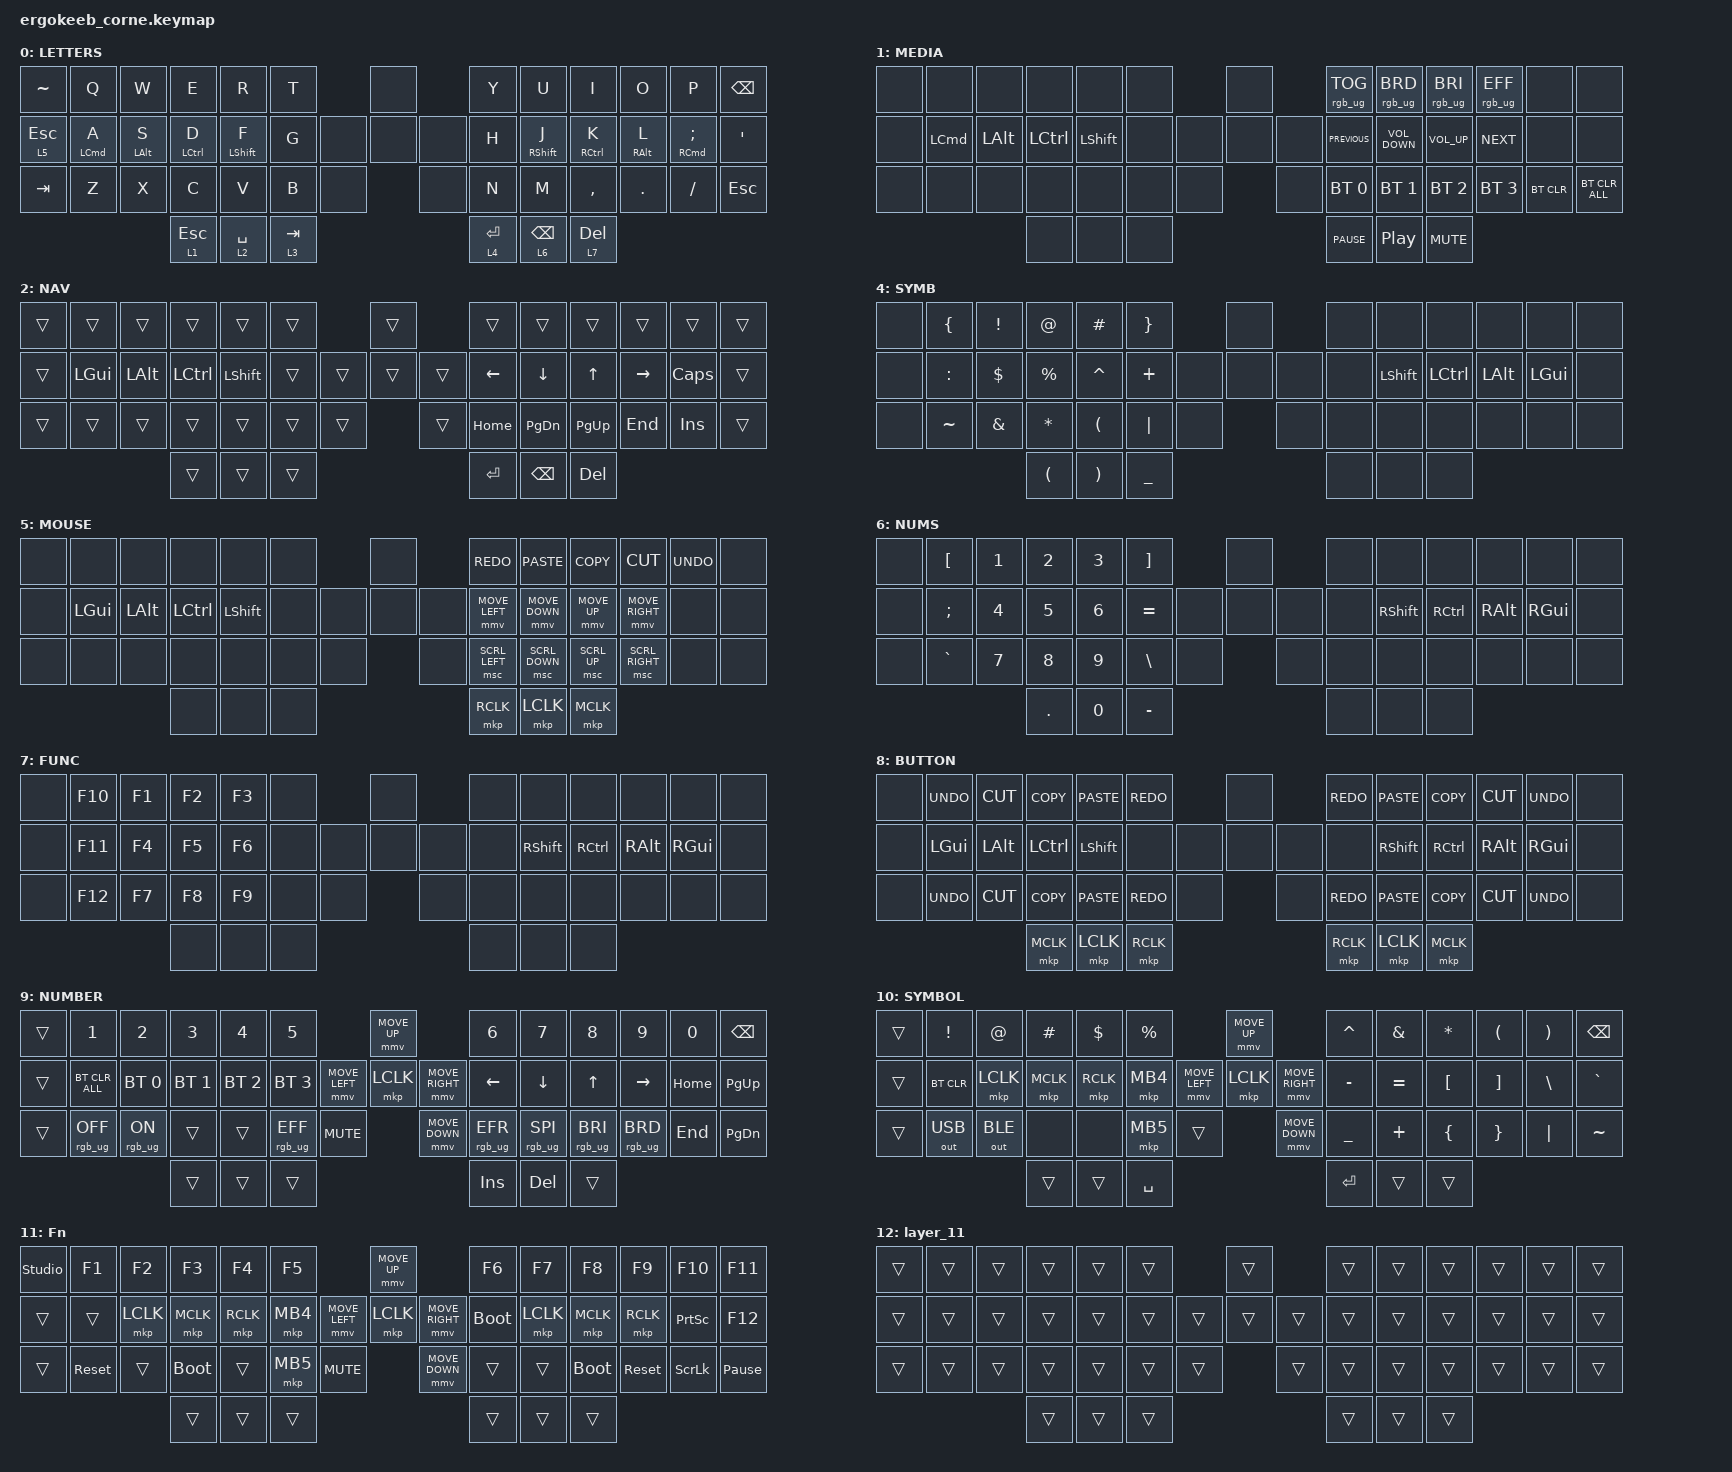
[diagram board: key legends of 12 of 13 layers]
#include <dt-bindings/zmk/mouse.h>
#include <input/processors.dtsi>
#include <behaviors.dtsi>
#include <dt-bindings/zmk/backlight.h>
#include <dt-bindings/zmk/bt.h>
#include <dt-bindings/zmk/keys.h>
#include <dt-bindings/zmk/outputs.h>
#include <dt-bindings/zmk/pointing.h>
#include <dt-bindings/zmk/rgb.h>

/*

   &mmv_input_listener {
       input-processors = <&zip_xy_scaler 2 1>;
   };

   &msc_input_listener {
       input-processors = <&zip_xy_scaler 2 1>;
   };

 */

#define ZMK_MOUSE_DEFAULT_MOVE_VAL 1200  // 600
#define ZMK_MOUSE_DEFAULT_SCRL_VAL 20    // 10

/ {
    behaviors {
        td0: td0 {
            compatible = "zmk,behavior-tap-dance";
            display-name = "Shift/Caps Lock Tap Dance";
            #binding-cells = <0>;
            bindings = <&kp LEFT_SHIFT>, <&kp CAPS>;
        };

        KPM: KPM {
            compatible = "zmk,behavior-hold-tap";
            label = "Key Press Mod";
            bindings = <&kp>, <&kp>;

            #binding-cells = <2>;
            tapping-term-ms = <280>;
            quick-tap-ms = <175>;
            flavor = "tap-preferred";
            hold-trigger-key-positions = <14 16 15 17 23 24 25 26 45 46 47 44 43 42 13 27>;
        };

        MLM: MLM {
            compatible = "zmk,behavior-hold-tap";
            label = "Momentary Layer Mod";
            bindings = <&mo>, <&kp>;

            #binding-cells = <2>;
            tapping-term-ms = <280>;
            quick-tap-ms = <175>;
            hold-trigger-key-positions = <42 43 44 45 46 46 47 13 27>;
            flavor = "tap-preferred";
        };
    };

    rgb_encoder: rgb_encoder {
        compatible = "zmk,behavior-sensor-rotate";
        #sensor-binding-cells = <0>;
        bindings = <&rgb_ug RGB_BRI>, <&rgb_ug RGB_BRD>;
    };

    scroll_encoder: scroll_encoder {
        compatible = "zmk,behavior-sensor-rotate";
        #sensor-binding-cells = <0>;
        bindings = <&msc SCRL_DOWN>, <&msc SCRL_UP>;

        tap-ms = <30>;
    };

    keymap {
        compatible = "zmk,keymap";

        LETTERS {
            display-name = "LETTERS";
            bindings = <
&kp TILDE      &kp Q                &kp W            &kp E                &kp R              &kp T                       &none         &kp Y         &kp U               &kp I                 &kp O             &kp P                    &kp BSPC
&MLM 5 ESCAPE  &KPM LEFT_COMMAND A  &KPM LEFT_ALT S  &KPM LEFT_CONTROL D  &KPM LEFT_SHIFT F  &kp G                &none  &none  &none  &kp H         &KPM RIGHT_SHIFT J  &KPM RIGHT_CONTROL K  &KPM RIGHT_ALT L  &KPM RIGHT_COMMAND SEMI  &kp SQT
&kp TAB        &kp Z                &kp X            &kp C                &kp V              &kp B       &none           &none         &kp N         &kp M               &kp COMMA             &kp DOT           &kp FSLH                 &kp ESC
                                                     &MLM 1 ESCAPE        &MLM 2 SPACE       &MLM 3 TAB                                &MLM 4 ENTER  &MLM 6 BACKSPACE    &MLM 7 DELETE
            >;
        };

        MEDIA {
            bindings = <
&none  &none             &none         &none             &none           &none                  &none         &rgb_ug RGB_TOG  &rgb_ug RGB_BRD    &rgb_ug RGB_BRI  &rgb_ug RGB_EFF  &none       &none
&none  &kp LEFT_COMMAND  &kp LEFT_ALT  &kp LEFT_CONTROL  &kp LEFT_SHIFT  &none           &none  &none  &none  &kp C_PREVIOUS   &kp C_VOLUME_DOWN  &kp C_VOLUME_UP  &kp C_NEXT       &none       &none
&none  &none             &none         &none             &none           &none  &none           &none         &bt BT_SEL 0     &bt BT_SEL 1       &bt BT_SEL 2     &bt BT_SEL 3     &bt BT_CLR  &bt BT_CLR_ALL
                                       &none             &none           &none                                &kp C_PAUSE      &kp C_PLAY_PAUSE   &kp K_MUTE
            >;

            label = "MEDIA";
        };

        NAV {
            bindings = <
&trans  &trans    &trans    &trans     &trans     &trans                    &trans          &trans     &trans         &trans        &trans     &trans        &trans
&trans  &kp LGUI  &kp LALT  &kp LCTRL  &kp LSHFT  &trans            &trans  &trans  &trans  &kp LEFT   &kp DOWN       &kp UP_ARROW  &kp RIGHT  &kp CAPSLOCK  &trans
&trans  &trans    &trans    &trans     &trans     &trans  &trans            &trans          &kp HOME   &kp PAGE_DOWN  &kp PAGE_UP   &kp END    &kp INSERT    &trans
                            &trans     &trans     &trans                                    &kp ENTER  &kp BSPC       &kp DELETE
            >;

            label = "NAV";
        };

        DISPLAY {
            bindings = <
&none  &none     &none     &none      &none      &none                  &none         &kp LC(LG(LEFT_ARROW))  &kp LC(LG(DOWN))          &kp LC(LG(UP_ARROW))       &kp LC(LG(RIGHT_ARROW))  &none                         &none
&none  &kp LGUI  &kp LALT  &kp LCTRL  &kp LSHFT  &none           &none  &none  &none  &kp LG(GRAVE)           &kp LA(LS(LEFT_BRACKET))  &kp LA(LS(RIGHT_BRACKET))  &kp LG(TAB)              &kp LA(LG(LC(LS(UP_ARROW))))  &none
&none  &none     &none     &none      &none      &none  &none           &none         &bl BL_TOG              &kp C_BRIGHTNESS_DEC      &kp C_BRIGHTNESS_INC       &bl BL_SET 100           &none                         &none
                           &none      &none      &none                                &none                   &none                     &none
            >;

            label = "DISPLAY";
        };

        SYMB {
            bindings = <
&none  &kp LEFT_BRACE  &kp EXCLAMATION  &kp AT_SIGN           &kp HASH               &kp RIGHT_BRACE                  &none         &none  &none      &none      &none     &none     &none
&none  &kp COLON       &kp DOLLAR       &kp PERCENT           &kp CARET              &kp PLUS                  &none  &none  &none  &none  &kp LSHFT  &kp LCTRL  &kp LALT  &kp LGUI  &none
&none  &kp TILDE       &kp AMPERSAND    &kp ASTERISK          &kp LEFT_PARENTHESIS   &kp PIPE         &none           &none         &none  &none      &none      &none     &none     &none
                                        &kp LEFT_PARENTHESIS  &kp RIGHT_PARENTHESIS  &kp UNDERSCORE                                 &none  &none      &none
            >;

            label = "SYMB";
        };

        MOUSE {
            bindings = <
&none  &none     &none     &none      &none      &none                  &none         &kp K_REDO      &kp K_PASTE     &kp K_COPY    &kp K_CUT        &kp K_UNDO  &none
&none  &kp LGUI  &kp LALT  &kp LCTRL  &kp LSHFT  &none           &none  &none  &none  &mmv MOVE_LEFT  &mmv MOVE_DOWN  &mmv MOVE_UP  &mmv MOVE_RIGHT  &none       &none
&none  &none     &none     &none      &none      &none  &none           &none         &msc SCRL_LEFT  &msc SCRL_DOWN  &msc SCRL_UP  &msc SCRL_RIGHT  &none       &none
                           &none      &none      &none                                &mkp RCLK       &mkp LCLK       &mkp MCLK
            >;

            label = "MOUSE";
        };

        NUMS {
            bindings = <
&none  &kp LBKT   &kp N1  &kp N2   &kp N3  &kp RBKT                   &none         &none  &none      &none      &none     &none     &none
&none  &kp SEMI   &kp N4  &kp N5   &kp N6  &kp EQUAL           &none  &none  &none  &none  &kp RSHFT  &kp RCTRL  &kp RALT  &kp RGUI  &none
&none  &kp GRAVE  &kp N7  &kp N8   &kp N9  &kp BSLH   &none           &none         &none  &none      &none      &none     &none     &none
                          &kp DOT  &kp N0  &kp MINUS                                &none  &none      &none
            >;

            label = "NUMS";
        };

        FUNC {
            bindings = <
&none  &kp F10  &kp F1  &kp F2  &kp F3  &none                  &none         &none  &none      &none      &none     &none     &none
&none  &kp F11  &kp F4  &kp F5  &kp F6  &none           &none  &none  &none  &none  &kp RSHFT  &kp RCTRL  &kp RALT  &kp RGUI  &none
&none  &kp F12  &kp F7  &kp F8  &kp F9  &none  &none           &none         &none  &none      &none      &none     &none     &none
                        &none   &none   &none                                &none  &none      &none
            >;

            label = "FUNC";
        };

        BUTTON {
            bindings = <
&none  &kp K_UNDO  &kp K_CUT  &kp K_COPY  &kp K_PASTE  &kp K_REDO                  &none         &kp K_REDO  &kp K_PASTE  &kp K_COPY  &kp K_CUT  &kp K_UNDO  &none
&none  &kp LGUI    &kp LALT   &kp LCTRL   &kp LSHFT    &none                &none  &none  &none  &none       &kp RSHFT    &kp RCTRL   &kp RALT   &kp RGUI    &none
&none  &kp K_UNDO  &kp K_CUT  &kp K_COPY  &kp K_PASTE  &kp K_REDO  &none           &none         &kp K_REDO  &kp K_PASTE  &kp K_COPY  &kp K_CUT  &kp K_UNDO  &none
                              &mkp MCLK   &mkp LCLK    &mkp RCLK                                 &mkp RCLK   &mkp LCLK    &mkp MCLK
            >;

            label = "BUTTON";
        };

        lower_layer {
            display-name = "NUMBER";
            bindings = <
&trans  &kp N1           &kp N2          &kp N3        &kp N4        &kp N5                                         &mmv MOVE_UP                     &kp N6           &kp N7           &kp N8           &kp N9           &kp N0    &kp BSPC
&trans  &bt BT_CLR_ALL   &bt BT_SEL 0    &bt BT_SEL 1  &bt BT_SEL 2  &bt BT_SEL 3                   &mmv MOVE_LEFT  &mkp LCLK       &mmv MOVE_RIGHT  &kp LEFT         &kp DOWN         &kp UP           &kp RIGHT        &kp HOME  &kp PG_UP
&trans  &rgb_ug RGB_OFF  &rgb_ug RGB_ON  &trans        &trans        &rgb_ug RGB_EFF  &kp C_MUTE                    &mmv MOVE_DOWN                   &rgb_ug RGB_EFR  &rgb_ug RGB_SPI  &rgb_ug RGB_BRI  &rgb_ug RGB_BRD  &kp END   &kp PG_DN
                                         &trans        &trans        &trans                                                                          &kp INS          &kp DEL          &trans
            >;

            sensor-bindings = <&scroll_encoder>;
        };

        raise_layer {
            display-name = "SYMBOL";
            bindings = <
&trans  &kp EXCL      &kp AT        &kp HASH   &kp DLLR   &kp PRCNT                            &mmv MOVE_UP                     &kp CARET  &kp AMPS   &kp ASTRK  &kp LPAR  &kp RPAR  &kp BSPC
&trans  &bt BT_CLR    &mkp LCLK     &mkp MCLK  &mkp RCLK  &mkp MB4             &mmv MOVE_LEFT  &mkp LCLK       &mmv MOVE_RIGHT  &kp MINUS  &kp EQUAL  &kp LBKT   &kp RBKT  &kp BSLH  &kp GRAVE
&trans  &out OUT_USB  &out OUT_BLE  &none      &none      &mkp MB5   &trans                    &mmv MOVE_DOWN                   &kp UNDER  &kp PLUS   &kp LBRC   &kp RBRC  &kp PIPE  &kp TILDE
                                    &trans     &trans     &kp SPACE                                                             &kp RET    &trans     &trans
            >;

            sensor-bindings = <&scroll_encoder>;
        };

        layer_3 {
            display-name = "Fn";
            bindings = <
&studio_unlock  &kp F1      &kp F2     &kp F3       &kp F4     &kp F5                                  &mmv MOVE_UP                     &kp F6       &kp F7     &kp F8       &kp F9      &kp F10          &kp F11
&trans          &trans      &mkp LCLK  &mkp MCLK    &mkp RCLK  &mkp MB4                &mmv MOVE_LEFT  &mkp LCLK       &mmv MOVE_RIGHT  &bootloader  &mkp LCLK  &mkp MCLK    &mkp RCLK   &kp PRINTSCREEN  &kp F12
&trans          &sys_reset  &trans     &bootloader  &trans     &mkp MB5  &kp C_MUTE                    &mmv MOVE_DOWN                   &trans       &trans     &bootloader  &sys_reset  &kp SCROLLLOCK   &kp PAUSE_BREAK
                                       &trans       &trans     &trans                                                                   &trans       &trans     &trans
            >;

            sensor-bindings = <&scroll_encoder>;
        };

        layer_11 {
            bindings = <
&trans  &trans  &trans  &trans  &trans  &trans                    &trans          &trans  &trans  &trans  &trans  &trans  &trans
&trans  &trans  &trans  &trans  &trans  &trans            &trans  &trans  &trans  &trans  &trans  &trans  &trans  &trans  &trans
&trans  &trans  &trans  &trans  &trans  &trans  &trans            &trans          &trans  &trans  &trans  &trans  &trans  &trans
                        &trans  &trans  &trans                                    &trans  &trans  &trans
            >;
        };
    };
};
